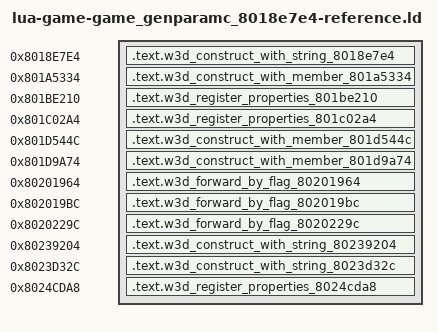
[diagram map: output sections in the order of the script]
/* Generated reference-only placements. All bodies are source-built. */
OUTPUT_FORMAT("elf32-powerpc")
OUTPUT_ARCH(powerpc)
ENTRY(w3d_construct_with_string_8018e7e4)
_SDA_BASE_ = 0x804b2540;
_SDA2_BASE_ = 0x804c2540;
fn_8018e26c = 0x8018e26c;
fn_801e81c8 = 0x801e81c8;
fn_801e8d9c = 0x801e8d9c;
fn_801eb834 = 0x801eb834;
fn_801ec52c = 0x801ec52c;
fn_801ecc6c = 0x801ecc6c;
fn_8020c5c0 = 0x8020c5c0;
fn_80238d88 = 0x80238d88;
fn_8023b59c = 0x8023b59c;
fn_80341884 = 0x80341884;
lbl_803abc8c = 0x803abc8c;
lbl_803abcc4 = 0x803abcc4;
lbl_803abcf4 = 0x803abcf4;
lbl_803ac314 = 0x803ac314;
lbl_803ac344 = 0x803ac344;
lbl_803ac374 = 0x803ac374;
lbl_803c4bfc = 0x803c4bfc;
lbl_803c4c2c = 0x803c4c2c;
lbl_803c4c5c = 0x803c4c5c;
lbl_80413160 = 0x80413160;
lbl_80413a78 = 0x80413a78;
lbl_80413ad0 = 0x80413ad0;
lbl_804166c0 = 0x804166c0;
lbl_80416708 = 0x80416708;
lbl_80416800 = 0x80416800;
lbl_80416848 = 0x80416848;
lbl_8041ac20 = 0x8041ac20;
lbl_8041b058 = 0x8041b058;
lbl_804b06a0 = 0x804b06a0;
SECTIONS {
  .text.w3d_construct_with_string_8018e7e4 0x8018e7e4 : { *(.text.w3d_construct_with_string_8018e7e4) }
  .text.w3d_construct_with_member_801a5334 0x801a5334 : { *(.text.w3d_construct_with_member_801a5334) }
  .text.w3d_register_properties_801be210 0x801be210 : { *(.text.w3d_register_properties_801be210) }
  .text.w3d_register_properties_801c02a4 0x801c02a4 : { *(.text.w3d_register_properties_801c02a4) }
  .text.w3d_construct_with_member_801d544c 0x801d544c : { *(.text.w3d_construct_with_member_801d544c) }
  .text.w3d_construct_with_member_801d9a74 0x801d9a74 : { *(.text.w3d_construct_with_member_801d9a74) }
  .text.w3d_forward_by_flag_80201964 0x80201964 : { *(.text.w3d_forward_by_flag_80201964) }
  .text.w3d_forward_by_flag_802019bc 0x802019bc : { *(.text.w3d_forward_by_flag_802019bc) }
  .text.w3d_forward_by_flag_8020229c 0x8020229c : { *(.text.w3d_forward_by_flag_8020229c) }
  .text.w3d_construct_with_string_80239204 0x80239204 : { *(.text.w3d_construct_with_string_80239204) }
  .text.w3d_construct_with_string_8023d32c 0x8023d32c : { *(.text.w3d_construct_with_string_8023d32c) }
  .text.w3d_register_properties_8024cda8 0x8024cda8 : { *(.text.w3d_register_properties_8024cda8) }
  /DISCARD/ : { *(.text*) *(.rodata*) *(.data*) *(.bss*) *(.sdata*) *(.sbss*) *(.comment) }
}
